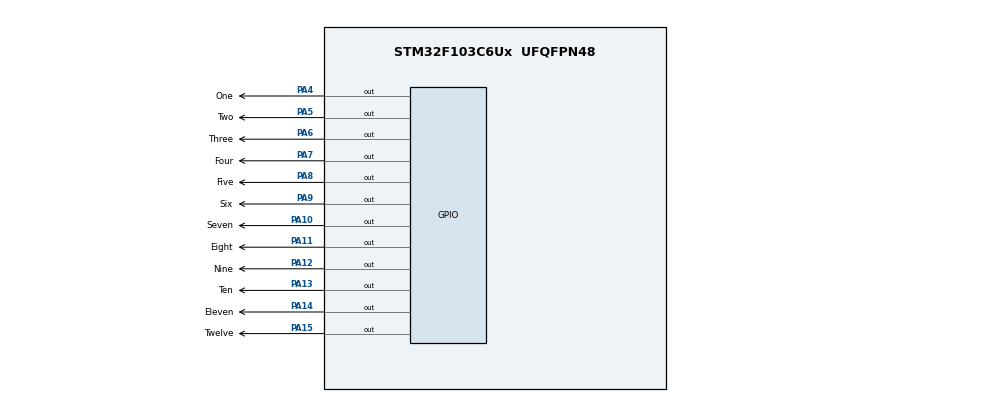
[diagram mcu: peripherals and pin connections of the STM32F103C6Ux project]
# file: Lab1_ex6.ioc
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Mcu.Family=STM32F1
Mcu.Name=STM32F103C6Ux
Mcu.Package=UFQFPN48
NVIC.PriorityGroup=NVIC_PRIORITYGROUP_4
PA10.GPIO_Label=Seven
PA10.Signal=GPIO_Output
PA11.GPIO_Label=Eight
PA11.Signal=GPIO_Output
PA12.GPIO_Label=Nine
PA12.Signal=GPIO_Output
PA13.GPIO_Label=Ten
PA13.Signal=GPIO_Output
PA14.GPIO_Label=Eleven
PA14.Signal=GPIO_Output
PA15.GPIO_Label=Twelve
PA15.Signal=GPIO_Output
PA4.GPIO_Label=One
PA4.Signal=GPIO_Output
PA5.GPIO_Label=Two
PA5.Signal=GPIO_Output
PA6.GPIO_Label=Three
PA6.Signal=GPIO_Output
PA7.GPIO_Label=Four
PA7.Signal=GPIO_Output
PA8.GPIO_Label=Five
PA8.Signal=GPIO_Output
PA9.GPIO_Label=Six
PA9.Signal=GPIO_Output
ProjectManager.HeapSize=0x200
ProjectManager.StackSize=0x400
ProjectManager.TargetToolchain=STM32CubeIDE
RCC.APB1Freq_Value=8000000
RCC.APB2Freq_Value=8000000
VP_SYS_VS_ND.Mode=No_Debug
board=custom

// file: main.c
/* USER CODE BEGIN Header */
/**
  ******************************************************************************
  * @file           : main.c
  * @brief          : Main program body
  ******************************************************************************
  * @attention
  *
  * <h2><center>&copy; Copyright (c) 2024 STMicroelectronics.
  * All rights reserved.</center></h2>
  *
  * This software component is licensed by ST under BSD 3-Clause license,
  * the "License"; You may not use this file except in compliance with the
  * License. You may obtain a copy of the License at:
  *                        opensource.org/licenses/BSD-3-Clause
  *
  ******************************************************************************
  */
/* USER CODE END Header */
#include "main.h"

void SystemClock_Config(void);
static void MX_GPIO_Init(void);

void clearAllClock()
{
	HAL_GPIO_WritePin ( One_GPIO_Port , One_Pin , GPIO_PIN_RESET ) ;
		  	HAL_GPIO_WritePin ( Two_GPIO_Port , Two_Pin , GPIO_PIN_RESET ) ;
		  	HAL_GPIO_WritePin ( Three_GPIO_Port , Three_Pin , GPIO_PIN_RESET ) ;
		  	HAL_GPIO_WritePin ( Four_GPIO_Port ,Four_Pin, GPIO_PIN_RESET ) ;
		  	HAL_GPIO_WritePin ( Five_GPIO_Port ,Five_Pin , GPIO_PIN_RESET ) ;
		  	HAL_GPIO_WritePin ( Six_GPIO_Port , Six_Pin , GPIO_PIN_RESET ) ;
		  	HAL_GPIO_WritePin ( Seven_GPIO_Port , Seven_Pin , GPIO_PIN_RESET ) ;
		  	HAL_GPIO_WritePin ( Eight_GPIO_Port , Eight_Pin , GPIO_PIN_RESET ) ;
		    HAL_GPIO_WritePin ( Nine_GPIO_Port ,Nine_Pin , GPIO_PIN_RESET ) ;
		  	HAL_GPIO_WritePin ( Ten_GPIO_Port , Ten_Pin , GPIO_PIN_RESET ) ;
		  	HAL_GPIO_WritePin ( Eleven_GPIO_Port ,Eleven_Pin, GPIO_PIN_RESET);
		  	HAL_GPIO_WritePin(Twelve_GPIO_Port, Twelve_Pin, GPIO_PIN_RESET);
};
void setNumberOnClock(int n)
{
	switch(n){
					case 1: HAL_GPIO_WritePin ( One_GPIO_Port , One_Pin , GPIO_PIN_SET ) ; break;
					case 2: HAL_GPIO_WritePin ( Two_GPIO_Port , Two_Pin , GPIO_PIN_SET ) ; break;
					case 3:	  HAL_GPIO_WritePin ( Three_GPIO_Port , Three_Pin , GPIO_PIN_SET ) ; break;
					case 4:	  HAL_GPIO_WritePin ( Four_GPIO_Port ,Four_Pin, GPIO_PIN_SET ) ; break;
					case 5:	  HAL_GPIO_WritePin ( Five_GPIO_Port ,Five_Pin , GPIO_PIN_SET ) ;break;
					case 6:	  HAL_GPIO_WritePin ( Six_GPIO_Port , Six_Pin , GPIO_PIN_SET ) ;break;
					case 7:	  HAL_GPIO_WritePin ( Seven_GPIO_Port , Seven_Pin , GPIO_PIN_SET ) ;break;
					case 8:	  HAL_GPIO_WritePin ( Eight_GPIO_Port , Eight_Pin , GPIO_PIN_SET ) ;break;
					case 9:	  HAL_GPIO_WritePin ( Nine_GPIO_Port ,Nine_Pin , GPIO_PIN_SET ) ;break;
					case 10:	  HAL_GPIO_WritePin ( Ten_GPIO_Port , Ten_Pin , GPIO_PIN_SET ) ;break;
					case 11:	  HAL_GPIO_WritePin ( Eleven_GPIO_Port , Eleven_Pin , GPIO_PIN_SET ) ;break;
					case 0:	  	HAL_GPIO_WritePin(Twelve_GPIO_Port, Twelve_Pin, GPIO_PIN_SET);break;
	}
};
void clearNumberOnClock(int n)
{
	switch(n){
					case 1: HAL_GPIO_WritePin ( One_GPIO_Port , One_Pin , GPIO_PIN_RESET ) ; break;
					case 2: HAL_GPIO_WritePin ( Two_GPIO_Port , Two_Pin , GPIO_PIN_RESET ) ; break;
					case 3:	  HAL_GPIO_WritePin ( Three_GPIO_Port , Three_Pin , GPIO_PIN_RESET ) ; break;
					case 4:	  HAL_GPIO_WritePin ( Four_GPIO_Port ,Four_Pin, GPIO_PIN_RESET ) ; break;
					case 5:	  HAL_GPIO_WritePin ( Five_GPIO_Port ,Five_Pin , GPIO_PIN_RESET ) ;break;
					case 6:	  HAL_GPIO_WritePin ( Six_GPIO_Port , Six_Pin , GPIO_PIN_RESET ) ;break;
					case 7:	  HAL_GPIO_WritePin ( Seven_GPIO_Port , Seven_Pin , GPIO_PIN_RESET ) ;break;
					case 8:	  HAL_GPIO_WritePin ( Eight_GPIO_Port , Eight_Pin , GPIO_PIN_RESET ) ;break;
					case 9:	  HAL_GPIO_WritePin ( Nine_GPIO_Port ,Nine_Pin , GPIO_PIN_RESET ) ;break;
					case 10:  HAL_GPIO_WritePin ( Ten_GPIO_Port , Ten_Pin , GPIO_PIN_RESET ) ;break;
					case 11:  HAL_GPIO_WritePin ( Eleven_GPIO_Port , Eleven_Pin , GPIO_PIN_RESET ) ;break;
					case 0:	  HAL_GPIO_WritePin(Twelve_GPIO_Port, Twelve_Pin, GPIO_PIN_RESET);break;
	}
};
int main(void)
{

  /* MCU Configuration--------------------------------------------------------*/

  /* Reset of all peripherals, Initializes the Flash interface and the Systick. */
  HAL_Init();

  /* Configure the system clock */
  SystemClock_Config();

  /* Initialize all configured peripherals */
  MX_GPIO_Init();

  /* Infinite loop */
  /* USER CODE BEGIN WHILE */
  int h = 0;
  int m = 0;
  int s = 0;
  while (1)
  {
    /* USER CODE END WHILE */
//	  HAL_GPIO_WritePin ( One_GPIO_Port , One_Pin , GPIO_PIN_SET ) ;
//	  HAL_GPIO_WritePin ( Two_GPIO_Port , Two_Pin , GPIO_PIN_SET ) ;
//	  HAL_GPIO_WritePin ( Three_GPIO_Port , Three_Pin , GPIO_PIN_SET ) ;
//	  HAL_GPIO_WritePin ( Four_GPIO_Port ,Four_Pin, GPIO_PIN_SET ) ;
//	  HAL_GPIO_WritePin ( Five_GPIO_Port ,Five_Pin , GPIO_PIN_SET ) ;
//	  HAL_GPIO_WritePin ( Six_GPIO_Port , Six_Pin , GPIO_PIN_SET ) ;
//	  HAL_GPIO_WritePin ( Seven_GPIO_Port , Seven_Pin , GPIO_PIN_SET ) ;
//	  HAL_GPIO_WritePin ( Eight_GPIO_Port , Eight_Pin , GPIO_PIN_SET ) ;
//	  HAL_GPIO_WritePin ( Nine_GPIO_Port ,Nine_Pin , GPIO_PIN_SET ) ;
//	  HAL_GPIO_WritePin ( Ten_GPIO_Port , Ten_Pin , GPIO_PIN_SET ) ;
//	  HAL_GPIO_WritePin ( Eleven_GPIO_Port , Eleven_Pin , GPIO_PIN_SET ) ;
//	  HAL_GPIO_WritePin(Twelve_GPIO_Port, Twelve_Pin, GPIO_PIN_SET);
//	  clearAllClock();
//	  HAL_Delay(1000);
//	  for (int n = 0; n < 13; n++)
//	  {
//		  setNumberOnClock(n);
//		  HAL_Delay(1000);
//	  }

	  int secDisplay = s/5;
	  int minDisplay = m/5;
	  if (minDisplay != secDisplay - 1 || h != secDisplay - 1) clearNumberOnClock(secDisplay-1);
	  if (minDisplay -1 != h) clearNumberOnClock(minDisplay-1);

	  setNumberOnClock(secDisplay);
	  setNumberOnClock(minDisplay);
	  setNumberOnClock(h);

	  s++;
	  if (s > 60) {s = 0; m++;}
	  	  if (m > 60) {m = 0; h++;}
	  	  if (h > 11) h = 0;

	  HAL_Delay(20);

  }
}

void SystemClock_Config(void)
{
  RCC_OscInitTypeDef RCC_OscInitStruct = {0};
  RCC_ClkInitTypeDef RCC_ClkInitStruct = {0};

  /** Initializes the RCC Oscillators according to the specified parameters
  * in the RCC_OscInitTypeDef structure.
  */
  RCC_OscInitStruct.OscillatorType = RCC_OSCILLATORTYPE_HSI;
  RCC_OscInitStruct.HSIState = RCC_HSI_ON;
  RCC_OscInitStruct.HSICalibrationValue = RCC_HSICALIBRATION_DEFAULT;
  RCC_OscInitStruct.PLL.PLLState = RCC_PLL_NONE;
  if (HAL_RCC_OscConfig(&RCC_OscInitStruct) != HAL_OK)
  {
    Error_Handler();
  }
  /** Initializes the CPU, AHB and APB buses clocks
  */
  RCC_ClkInitStruct.ClockType = RCC_CLOCKTYPE_HCLK|RCC_CLOCKTYPE_SYSCLK
                              |RCC_CLOCKTYPE_PCLK1|RCC_CLOCKTYPE_PCLK2;
  RCC_ClkInitStruct.SYSCLKSource = RCC_SYSCLKSOURCE_HSI;
  RCC_ClkInitStruct.AHBCLKDivider = RCC_SYSCLK_DIV1;
  RCC_ClkInitStruct.APB1CLKDivider = RCC_HCLK_DIV1;
  RCC_ClkInitStruct.APB2CLKDivider = RCC_HCLK_DIV1;

  if (HAL_RCC_ClockConfig(&RCC_ClkInitStruct, FLASH_LATENCY_0) != HAL_OK)
  {
    Error_Handler();
  }
}

static void MX_GPIO_Init(void)
{
  GPIO_InitTypeDef GPIO_InitStruct = {0};

  /* GPIO Ports Clock Enable */
  __HAL_RCC_GPIOA_CLK_ENABLE();

  /*Configure GPIO pin Output Level */
  HAL_GPIO_WritePin(GPIOA, One_Pin|Two_Pin|Three_Pin|Four_Pin
                          |Five_Pin|Six_Pin|Seven_Pin|Eight_Pin
                          |Nine_Pin|Ten_Pin|Eleven_Pin|Twelve_Pin, GPIO_PIN_RESET);

  /*Configure GPIO pins : One_Pin Two_Pin Three_Pin Four_Pin
                           Five_Pin Six_Pin Seven_Pin Eight_Pin
                           Nine_Pin Ten_Pin Eleven_Pin Twelve_Pin */
  GPIO_InitStruct.Pin = One_Pin|Two_Pin|Three_Pin|Four_Pin
                          |Five_Pin|Six_Pin|Seven_Pin|Eight_Pin
                          |Nine_Pin|Ten_Pin|Eleven_Pin|Twelve_Pin;
  GPIO_InitStruct.Mode = GPIO_MODE_OUTPUT_PP;
  GPIO_InitStruct.Pull = GPIO_NOPULL;
  GPIO_InitStruct.Speed = GPIO_SPEED_FREQ_LOW;
  HAL_GPIO_Init(GPIOA, &GPIO_InitStruct);

}

void Error_Handler(void)
{
  __disable_irq();
  while (1)
  {
  }
}

/************************ (C) COPYRIGHT STMicroelectronics *****END OF FILE****/
